# PIC32CX1025MTSH128S1 register map
Vendor: Microchip Technology; Series: PIC32CXMTSH; File version: 0
CPU: CM4 r0p1, selectable endian, MPU, FPU, 4 interrupt priority bits
Registers are 32-bit, read-write, reset 0x0 unless marked. A register's access mark holds for its fields unless they carry their own. Offsets are from the block's base; [hi:lo] are bit positions; 'fields as' and 'values as' point back to an identical list.

## DWDT — Dual Watchdog Timer
Base 0x40052000; register names take the prefix DWDT_
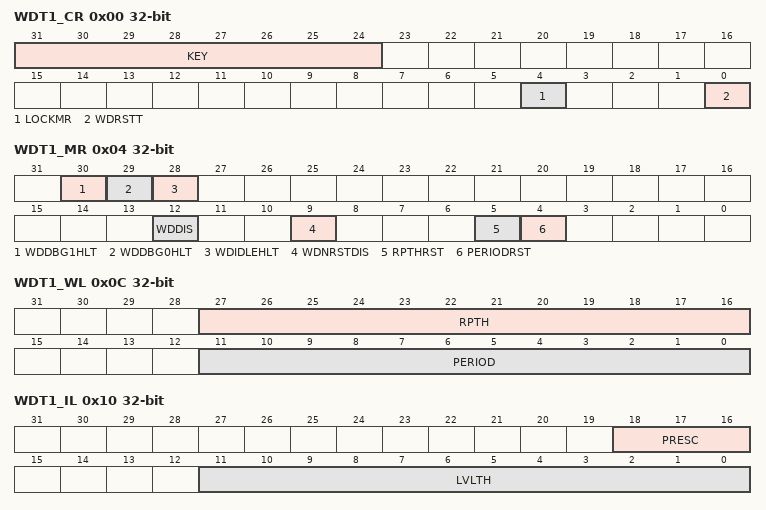
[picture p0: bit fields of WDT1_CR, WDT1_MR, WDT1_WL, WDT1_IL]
0x00 WDT1_CR wo — Watchdog 1 Control Register
  [31:24] KEY — Password
    165=PASSWD (Writing any other value in this field aborts the write operation.)
  [4] LOCKMR — Lock Mode Register Write Access
  [0] WDRSTT — Watchdog Restart
0x04 WDT1_MR — Watchdog 1 Mode Register
  [30] WDDBG1HLT — Watchdog Core 1 Debug Halt
  [29] WDDBG0HLT — Watchdog Core 0 Debug Halt
  [28] WDIDLEHLT — Watchdog Idle Halt
  [12] WDDIS — Watchdog Disable
  [9] WDNRSTDIS — Watchdog Reset NRST Pin Disable
  [5] RPTHRST — Repeat Threshold Reset Enable
  [4] PERIODRST — Watchdog Overflow Period Reset Enable
0x08 WDT1_VR ro — Watchdog 1 Value Register
  [11:0] COUNTER — Watchdog Down Counter Value
0x0C WDT1_WL — Watchdog 1 Window Level Register
  [27:16] RPTH — Repeat Threshold
  [11:0] PERIOD — Watchdog Period
0x10 WDT1_IL — Watchdog 1 Interrupt Level Register
  [18:16] PRESC — Prescaler Ratio
    0=RATIO128 (The watchdog counter decreased when the prescaler reaches 128.); 1=RATIO64 (The watchdog counter decreased when the prescaler reaches 64.); 2=RATIO32 (The watchdog counter decreased when the prescaler reaches 32.); 3=RATIO16 (The watchdog counter decreased when the prescaler reaches 16.); 4=RATIO8 (The watchdog counter decreased when the prescaler reaches 8.); 5=RATIO4 (The watchdog counter decreased when the prescaler reaches 4.); 6=RATIO2 (The watchdog counter decreased when the prescaler reaches 2.); 7=RATIO1 (The watchdog counter decreased when the prescaler reaches 1.)
  [11:0] LVLTH — Level Threshold
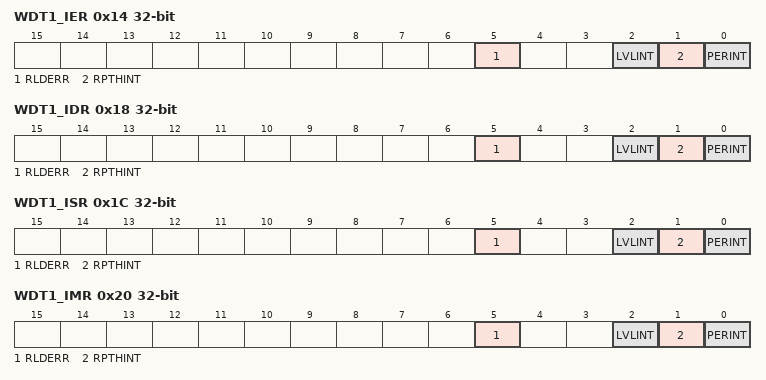
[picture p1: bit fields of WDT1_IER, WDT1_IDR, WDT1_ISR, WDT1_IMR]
0x14 WDT1_IER wo — Watchdog 1 Interrupt Enable Register
  [5] RLDERR — Reload Command Error Interrupt Enable
  [2] LVLINT — Interrupt Level Threshold Interrupt Enable
  [1] RPTHINT — Reload Repeat Period Interrupt Enable
  [0] PERINT — Overflow Period Interrupt Enable
0x18 WDT1_IDR wo — Watchdog 1 Interrupt Disable Register
  [5] RLDERR — Reload Command Error Interrupt Disable
  [2] LVLINT — Interrupt Level Threshold Interrupt Disable
  [1] RPTHINT — Reload Repeat Period Interrupt Disable
  [0] PERINT — Overflow Period Interrupt Disable
0x1C WDT1_ISR ro — Watchdog 1 Interrupt Status Register
  [5] RLDERR — Reload Command Error Status (cleared on read)
  [2] LVLINT — Interrupt Level Threshold Status (cleared on read)
  [1] RPTHINT — Reload Repeat Period Status (cleared on read)
  [0] PERINT — Overflow Period Status (cleared on read)
0x20 WDT1_IMR ro — Watchdog 1 Interrupt Mask Register
  [5] RLDERR — Reload Command Error Interrupt Mask
  [2] LVLINT — Interrupt Level Threshold Interrupt Mask
  [1] RPTHINT — Reload Repeat Period Interrupt Mask
  [0] PERINT — Overflow Period Interrupt Mask
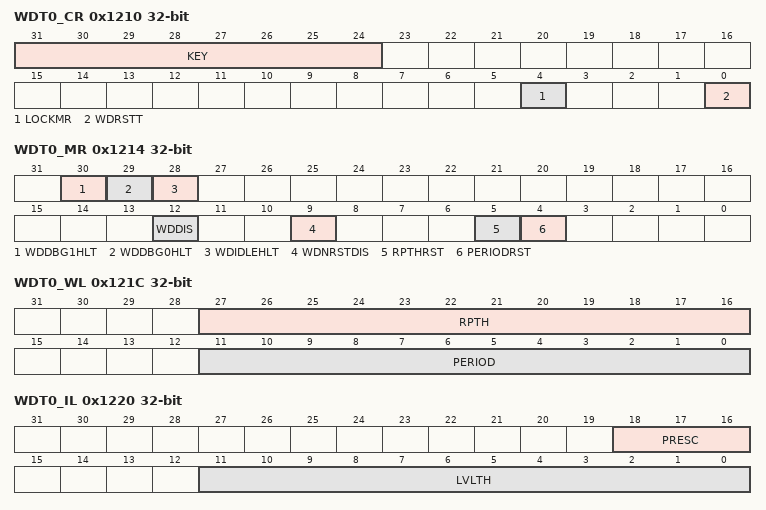
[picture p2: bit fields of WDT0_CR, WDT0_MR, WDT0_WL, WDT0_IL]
0x1210 WDT0_CR wo — Watchdog 0 Control Register
  fields as WDT1_CR
0x1214 WDT0_MR — Watchdog 0 Mode Register
  [30] WDDBG1HLT — Watchdog Core 1 Debug Halt
  [29] WDDBG0HLT — Watchdog Core 0 Debug Halt
  [28] WDIDLEHLT — Watchdog Idle Halt
  [12] WDDIS — Watchdog Disable
  [9] WDNRSTDIS — Watchdog NRST Disable
  [5] RPTHRST — Repeat Threshold Reset
  [4] PERIODRST — Period Reset
0x1218 WDT0_VR ro — Watchdog 0 Value Register
  [11:0] COUNTER — Watchdog Down Counter Value
0x121C WDT0_WL — Watchdog 0 Window Level
  [27:16] RPTH — Repeat Threshold
  [11:0] PERIOD — Watchdog Period
0x1220 WDT0_IL — Watchdog 0 Interrupt Level
  fields as WDT1_IL
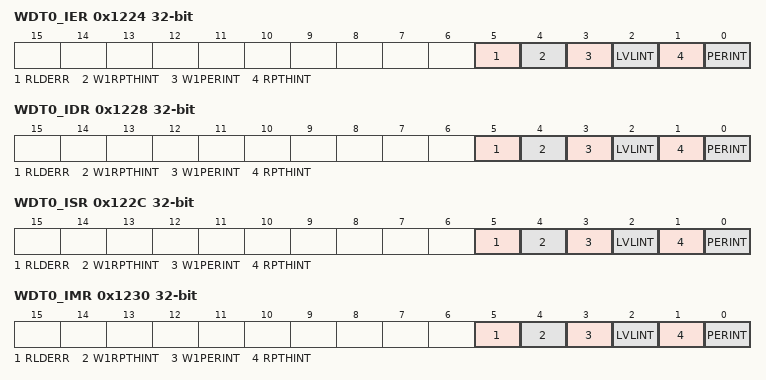
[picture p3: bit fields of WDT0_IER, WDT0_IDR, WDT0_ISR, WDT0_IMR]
0x1224 WDT0_IER wo — Watchdog 0 Interrupt Enable Register
  [5] RLDERR — Reload Command Error Interrupt Enable
  [4] W1RPTHINT — Watchdog 1 Repeat Threshold Interrupt Enable
  [3] W1PERINT — Watchdog 1 Overflow Interrupt Enable
  [2] LVLINT — Interrupt Level Threshold Interrupt Enable
  [1] RPTHINT — Reload Repeat Period Interrupt Enable
  [0] PERINT — Overflow Period Interrupt Enable
0x1228 WDT0_IDR wo — Watchdog 0 Interrupt Disable Register
  [5] RLDERR — Reload Command Error Interrupt Disable
  [4] W1RPTHINT — Watchdog 1 Repeat Threshold Interrupt Disable
  [3] W1PERINT — Watchdog 1 Overflow Interrupt Disable
  [2] LVLINT — Interrupt Level Threshold Interrupt Disable
  [1] RPTHINT — Reload Repeat Period Interrupt Disable
  [0] PERINT — Overflow Period Interrupt Disable
0x122C WDT0_ISR ro — Watchdog 0 Interrupt Status Register
  [5] RLDERR — Reload Command Error Status (cleared on read)
  [4] W1RPTHINT — Watchdog 1 Repeat Threshold Interrupt Status
  [3] W1PERINT — Watchdog 1 Overflow Interrupt Status
  [2] LVLINT — Interrupt Level Threshold Status (cleared on read)
  [1] RPTHINT — Reload Repeat Period Status (cleared on read)
  [0] PERINT — Overflow Period Status (cleared on read)
0x1230 WDT0_IMR ro — Watchdog 0 Interrupt Mask Register
  [5] RLDERR — Reload Command Error Interrupt Mask
  [4] W1RPTHINT — Watchdog 1 Repeat Threshold Interrupt Mask
  [3] W1PERINT — Watchdog 1 Overflow Interrupt Mask
  [2] LVLINT — Interrupt Level Threshold Interrupt Mask
  [1] RPTHINT — Reload Repeat Period Interrupt Mask
  [0] PERINT — Overflow Period Interrupt Mask
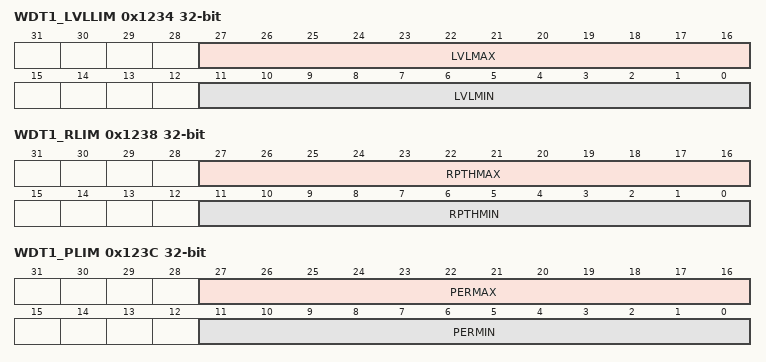
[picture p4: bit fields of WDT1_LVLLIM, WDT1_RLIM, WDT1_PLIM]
0x1234 WDT1_LVLLIM — Watchdog 1 Level Limits Register
  [27:16] LVLMAX — Maximum Level
  [11:0] LVLMIN — Minimum Level
0x1238 WDT1_RLIM — Watchdog 1 Repeat Limits Register
  [27:16] RPTHMAX — Maximum Repeat Threshold
  [11:0] RPTHMIN — Minimum Repeat Threshold
0x123C WDT1_PLIM — Watchdog 1 Period Limits Register
  [27:16] PERMAX — Maximum Period
  [11:0] PERMIN — Minimum Period
